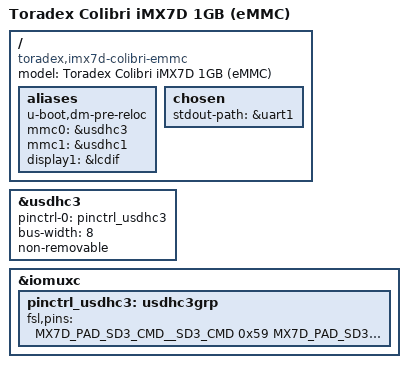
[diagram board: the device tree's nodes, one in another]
// SPDX-License-Identifier: GPL-2.0+ OR X11
/*
 * Copyright 2019 Toradex AG
 */

/dts-v1/;
#include "imx7-colibri.dtsi"

/ {
	model = "Toradex Colibri iMX7D 1GB (eMMC)";
	compatible = "toradex,imx7d-colibri-emmc", "fsl,imx7d";

	aliases {
		u-boot,dm-pre-reloc;
		mmc0 = &usdhc3;
		mmc1 = &usdhc1;
		display1 = &lcdif;
	};

	chosen {
		stdout-path = &uart1;
	};
};

&usdhc3 {
	pinctrl-names = "default";
	pinctrl-0 = <&pinctrl_usdhc3>;
	bus-width = <8>;
	non-removable;
	status = "okay";
};

&iomuxc {
	pinctrl_usdhc3: usdhc3grp {
		fsl,pins = <
			MX7D_PAD_SD3_CMD__SD3_CMD		0x59
			MX7D_PAD_SD3_CLK__SD3_CLK		0x19
			MX7D_PAD_SD3_DATA0__SD3_DATA0		0x59
			MX7D_PAD_SD3_DATA1__SD3_DATA1		0x59
			MX7D_PAD_SD3_DATA2__SD3_DATA2		0x59
			MX7D_PAD_SD3_DATA3__SD3_DATA3		0x59
			MX7D_PAD_SD3_DATA4__SD3_DATA4		0x59
			MX7D_PAD_SD3_DATA5__SD3_DATA5		0x59
			MX7D_PAD_SD3_DATA6__SD3_DATA6		0x59
			MX7D_PAD_SD3_DATA7__SD3_DATA7		0x59
			MX7D_PAD_SD3_STROBE__SD3_STROBE         0x19
		>;
	};
};
